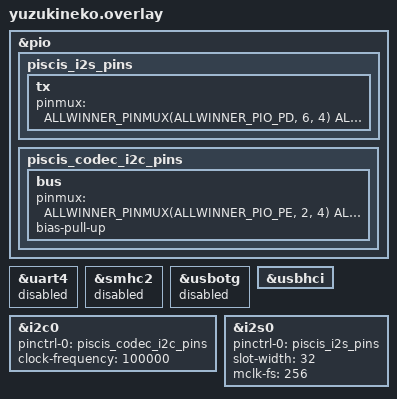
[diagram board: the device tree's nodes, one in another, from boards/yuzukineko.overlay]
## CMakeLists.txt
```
cmake_minimum_required(VERSION 3.20.0)
find_package(Zephyr REQUIRED HINTS $ENV{ZEPHYR_BASE})
project(piscis_standalone)
target_include_directories(app PRIVATE core organ synth)
target_sources(app PRIVATE src/main.cpp src/midi_host.c core/mdaEPiano.cpp)
target_compile_options(app PRIVATE $<$<COMPILE_LANGUAGE:CXX>:-fno-threadsafe-statics>)
```

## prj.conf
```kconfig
CONFIG_CPP=y
CONFIG_STD_CPP17=y
CONFIG_FPU=y
CONFIG_FPU_SHARING=y
CONFIG_CHERRYUSB=y
CONFIG_CHERRYUSB_HOST=y
CONFIG_CHERRYUSB_HOST_EHCI_CUSTOM=y
CONFIG_USBHOST_REQUEST_BUFFER_LEN=2048
CONFIG_I2C=y
CONFIG_I2S=y
CONFIG_DMA=y
CONFIG_MAIN_STACK_SIZE=16384
CONFIG_SYSTEM_WORKQUEUE_STACK_SIZE=2048
CONFIG_HEAP_MEM_POOL_SIZE=131072
CONFIG_CONSOLE=y
CONFIG_UART_CONSOLE=y
CONFIG_PRINTK=y
CONFIG_SHELL=n
CONFIG_DEVMEM_SHELL=n
CONFIG_DISPLAY=n
CONFIG_G2D=n
```

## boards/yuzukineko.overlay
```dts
/* PISCIS carrier layout from eed377f8b195, subject to physical-board check. */
&pio {
    piscis_i2s_pins: piscis_i2s_pins {
        tx {
            pinmux = <ALLWINNER_PINMUX(ALLWINNER_PIO_PD, 6, 4)
                      ALLWINNER_PINMUX(ALLWINNER_PIO_PD, 7, 4)
                      ALLWINNER_PINMUX(ALLWINNER_PIO_PD, 8, 4)
                      ALLWINNER_PINMUX(ALLWINNER_PIO_PD, 9, 4)>;
        };
    };
    piscis_codec_i2c_pins: piscis_codec_i2c_pins {
        bus {
            pinmux = <ALLWINNER_PINMUX(ALLWINNER_PIO_PE, 2, 4)
                      ALLWINNER_PINMUX(ALLWINNER_PIO_PE, 3, 4)>;
            bias-pull-up;
        };
    };
};

&uart4 { status = "disabled"; };
&smhc2 { status = "disabled"; };
&usbotg { status = "disabled"; };
&usbhci { status = "okay"; };

&i2c0 {
    status = "okay";
    pinctrl-0 = <&piscis_codec_i2c_pins>;
    pinctrl-names = "default";
    clock-frequency = <100000>;
};

&i2s0 {
    status = "okay";
    pinctrl-0 = <&piscis_i2s_pins>;
    pinctrl-names = "default";
    slot-width = <32>;
    mclk-fs = <256>;
};
```

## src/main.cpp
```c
#include <zephyr/device.h>
#include <zephyr/drivers/i2c.h>
#include <zephyr/drivers/i2s.h>
#include <zephyr/kernel.h>
#include <zephyr/sys/printk.h>

#include <errno.h>
#include <string.h>
#include "DualSynth.h"
#include "MidiInput.h"

extern "C" {
#include "midi_host.h"
}

namespace {
constexpr unsigned frames = 256;
// Leave two queued blocks after the driver fills its four DMA periods.
constexpr unsigned startup_blocks = 6;
constexpr size_t block_bytes = frames * 2 * sizeof(int16_t);
constexpr uint8_t codec_address = 0x10; // 7-bit I2C address with CE grounded
constexpr uint8_t dac_control3 = 0x19;
constexpr uint8_t dac_mute = 0x04;

const struct device *const i2c = DEVICE_DT_GET(DT_NODELABEL(i2c0));
const struct device *const i2s = DEVICE_DT_GET(DT_NODELABEL(i2s0));
float left[frames], right[frames];
K_MEM_SLAB_DEFINE(audio_blocks, block_bytes, startup_blocks, 64);
K_MSGQ_DEFINE(midi_events, sizeof(struct midi_event), 128, 4);
K_THREAD_STACK_DEFINE(midi_stack, 4096);
struct k_thread midi_thread;

class PlaybackVolume {
    static constexpr float startup_gain = 16.0f;
    static constexpr float max_gain = 80.0f; // +20 dB over the previous 8x maximum
    // Keep some digital peak headroom while letting chords build higher peaks.
    static constexpr float ceiling = 0.82f;
    float gain = startup_gain;
    float target = startup_gain;
    float limiter_gain = 1.0f;
    float pending_peak = 0.0f;
    float pending_left[frames]{};
    float pending_right[frames]{};

    static float magnitude(float sample)
    {
        return sample < 0 ? -sample : sample;
    }

public:
    void set(uint8_t value)
    {
        // Keep finer control at lower levels with the wider gain range.
        const float position = value / 127.0f;
        const float squared_position = position * position;
        target = max_gain * squared_position * squared_position;
    }

    void interleave(int16_t *pcm)
    {
        float peak = 0.0f;
        const float step = (target - gain) / frames;
        for (unsigned i = 0; i < frames; ++i) {
            const float level = gain + step * (i + 1);
            left[i] *= level;
            right[i] *= level;
            const float l = magnitude(left[i]);
            const float r = magnitude(right[i]);
            if (l > peak) peak = l;
            if (r > peak) peak = r;
        }
        gain = target;

        // Delay one block. This lets the gain ramp down before a loud chord
        // arrives, while a slower release keeps it from following the waveform.
        const float largest = peak > pending_peak ? peak : pending_peak;
        const float safe_gain = largest > ceiling ? ceiling / largest : 1.0f;
        const float recovery = limiter_gain + (1.0f - limiter_gain) * 0.08f;
        const float next_gain = recovery < safe_gain ? recovery : safe_gain;
        const float limiter_step = (next_gain - limiter_gain) / frames;
        for (unsigned i = 0; i < frames; ++i) {
            const float level = (limiter_gain + limiter_step * (i + 1)) * 32767.0f;
            pcm[2 * i] = static_cast<int16_t>(pending_left[i] * level);
            pcm[2 * i + 1] = static_cast<int16_t>(pending_right[i] * level);
            pending_left[i] = left[i];
            pending_right[i] = right[i];
        }
        limiter_gain = next_gain;
        pending_peak = peak;
    }
};

PlaybackVolume playback_volume;

int codec_write(uint8_t reg, uint8_t value)
{
    return i2c_reg_write_byte(i2c, codec_address, reg, value);
}

int codec_prepare()
{
    uint8_t reg_value = 0;
    int ret = i2c_reg_read_byte(i2c, codec_address, 0x00, &reg_value);
    if (ret) {
        printk("ES8388 did not respond at 0x10: %d\n", ret);
        return ret;
    }

    // Playback path from the ES8388 register map. CE is strapped low on the
    // PISCIS carrier and J5 is fed by LOUT1/ROUT1.
    constexpr struct { uint8_t reg, value; } setup[] = {
        {dac_control3, dac_mute},
        {0x01, 0x50}, // Reference and analog power
        {0x02, 0x00}, // Chip normal operation
        {0x03, 0xff}, // ADC off
        {0x04, 0xc0}, // DAC and analog outputs off during configuration
        {0x00, 0x12}, // Playback reference configuration
        {0x08, 0x00}, // F101 supplies clocks
        {0x17, 0x18}, // Philips I2S, 16-bit samples
        {0x18, 0x02}, // MCLK = 256 x sample rate
        {0x1a, 0x00}, {0x1b, 0x00}, // Digital playback volume (0 dB)
        {0x26, 0x00},
        {0x27, 0x90}, {0x2a, 0x90}, // Left/right DAC to matching analog mixer
        {0x2b, 0x80}, // Shared LRCK
        {0x2d, 0x00},
        {0x2e, 0x21}, {0x2f, 0x21}, // LOUT1/ROUT1 analog gain +3 dB
        {0x04, 0x30}, // Enable DAC and the LOUT1/ROUT1 pair
    };
    for (const auto &entry : setup) {
        ret = codec_write(entry.reg, entry.value);
        if (ret) {
            printk("ES8388 register 0x%02x failed: %d\n", entry.reg, ret);
            return ret;
        }
    }
    k_msleep(100);
    return 0;
}

int queue_audio(DualSynth *synth)
{
    void *block;
    int ret = k_mem_slab_alloc(&audio_blocks, &block, K_MSEC(100));
    if (ret) return ret;
    if (synth) {
        synth->render(left, right, frames);
        playback_volume.interleave(static_cast<int16_t *>(block));
    } else {
        memset(block, 0, block_bytes);
    }
    ret = i2s_write(i2s, block, block_bytes);
    if (ret) k_mem_slab_free(&audio_blocks, block);
    return ret;
}

int audio_start()
{
    if (!device_is_ready(i2c) || !device_is_ready(i2s)) return -ENODEV;
    int ret = codec_prepare();
    if (ret) return ret;
    const struct i2s_config cfg = {
        .word_size = 16,
        .channels = 2,
        .format = I2S_FMT_DATA_FORMAT_I2S,
        .options = I2S_OPT_BIT_CLK_MASTER | I2S_OPT_FRAME_CLK_MASTER,
        .frame_clk_freq = 44100,
        .mem_slab = &audio_blocks,
        .block_size = block_bytes,
        .timeout = 100,
    };
    ret = i2s_configure(i2s, I2S_DIR_TX, &cfg);
    if (ret) return ret;
    for (unsigned i = 0; i < startup_blocks && !ret; ++i) ret = queue_audio(nullptr);
    if (!ret) ret = i2s_trigger(i2s, I2S_DIR_TX, I2S_TRIGGER_START);
    if (!ret) ret = codec_write(dac_control3, 0x00);
    if (ret) i2s_trigger(i2s, I2S_DIR_TX, I2S_TRIGGER_DROP);
    return ret;
}

void midi_receiver(void *, void *, void *)
{
    const int ret = midi_host_start();
    if (ret) {
        printk("USB host initialization failed: %d\n", ret);
        return;
    }
    for (;;) {
        midi_host_poll();
        k_msleep(1);
    }
}

int play_status_note(DualSynth &synth, int note)
{
    // Render a brief note before accepting live keys. Use the same audio path
    // and gain as normal playback so the two audible checkpoints are meaningful.
    synth.reset();
    synth.noteOn(note, 80);
    for (unsigned i = 0; i < 34; ++i) {
        if (i == 19) synth.noteOn(note, 0);
        const int ret = queue_audio(&synth);
        if (ret) return ret;
    }
    synth.reset();
    return 0;
}

}

extern "C" void midi_event_push(const struct midi_event *event)
{
    if (k_msgq_put(&midi_events, event, K_NO_WAIT) != 0) {
        k_msgq_purge(&midi_events);
        midi_event reset{};
        reset.type = MIDI_RESET;
        k_msgq_put(&midi_events, &reset, K_NO_WAIT);
        k_msgq_put(&midi_events, event, K_NO_WAIT);
    }
}

int main()
{
    static DualSynth synth;
    static MidiInput midi(synth);
    int ret = audio_start();
    if (ret) {
        printk("Headphone output initialization failed: %d\n", ret);
        return ret;
    }
    ret = play_status_note(synth, 60);
    if (ret) {
        codec_write(dac_control3, dac_mute);
        i2s_trigger(i2s, I2S_DIR_TX, I2S_TRIGGER_DROP);
        printk("Startup tone failed: %d\n", ret);
        return ret;
    }
    k_thread_create(&midi_thread, midi_stack, K_THREAD_STACK_SIZEOF(midi_stack),
                    midi_receiver, nullptr, nullptr, nullptr, 5, 0, K_NO_WAIT);
    printk("PISCIS ready: all MIDI channels, ES8388 44100 Hz\n");
    for (;;) {
        midi_event event;
        for (unsigned i = 0; i < 32 && k_msgq_get(&midi_events, &event, K_NO_WAIT) == 0; ++i) {
            if (event.type == MIDI_CONNECTED) {
                midi.reset();
                printk("MIDI keyboard ready, IN=0x%02x\n", event.key);
                ret = play_status_note(synth, 72);
                if (ret) break;
            } else if (event.type == MIDI_DISCONNECTED || event.type == MIDI_RESET) {
                midi.reset();
            } else if (event.type == MIDI_ERROR) {
                printk("MIDI input error: %d\n", event.detail);
            } else if (event.type == MIDI_VOLUME) {
                playback_volume.set(event.value);
            } else {
                midi.apply(event);
            }
        }
        if (!ret) ret = queue_audio(&synth);
        if (ret) {
            codec_write(dac_control3, dac_mute);
            i2s_trigger(i2s, I2S_DIR_TX, I2S_TRIGGER_DROP);
            printk("Audio output stopped: %d\n", ret);
            return ret;
        }
    }
}
```

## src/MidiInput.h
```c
#pragma once

#include <stdint.h>
#include <string.h>
#include "DualSynth.h"

extern "C" {
#include "midi_host.h"
}

// Merge the keyboard's cables and channels into one instrument. Keep note
// ownership per source so releasing a key on one channel cannot silence
// the same pitch while another channel still holds it.
class MidiInput {
    static constexpr unsigned channel_count = 16;
    static constexpr unsigned cable_count = 16;
    static constexpr unsigned note_count = 128;

    struct Source {
        bool held[note_count];
        bool sustain;
    };

    DualSynth &synth;
    Source sources[cable_count][channel_count]{};
    uint16_t note_holders[note_count]{};
    unsigned sustain_sources = 0;

    void clear()
    {
        memset(sources, 0, sizeof(sources));
        memset(note_holders, 0, sizeof(note_holders));
        sustain_sources = 0;
    }

    void release(Source &source, unsigned note)
    {
        if (!source.held[note]) return;
        source.held[note] = false;
        if (--note_holders[note] == 0) synth.noteOn(note, 0);
    }

    void set_sustain(Source &source, bool pressed)
    {
        if (source.sustain == pressed) return;
        const bool was_sustained = sustain_sources != 0;
        source.sustain = pressed;
        if (pressed) {
            ++sustain_sources;
        } else {
            --sustain_sources;
        }
        if (was_sustained != (sustain_sources != 0)) synth.sustain(sustain_sources != 0);
    }

public:
    explicit MidiInput(DualSynth &engine) : synth(engine) {}

    void reset()
    {
        synth.reset();
        clear();
    }

    void apply(const midi_event &event)
    {
        if (event.cable >= cable_count || event.channel >= channel_count ||
            event.key >= note_count) return;
        Source &source = sources[event.cable][event.channel];
        switch (event.type) {
        case MIDI_NOTE_ON:
            if (!source.held[event.key]) {
                source.held[event.key] = true;
                ++note_holders[event.key];
            }
            synth.noteOn(event.key, event.value);
            break;
        case MIDI_NOTE_OFF:
            release(source, event.key);
            break;
        case MIDI_SUSTAIN:
            set_sustain(source, event.value >= 64);
            break;
        case MIDI_PROGRAM:
            if (event.value <= 2 && synth.configure(event.value, 0, 100, 100)) clear();
            break;
        case MIDI_ALL_NOTES_OFF:
            if (event.key == 120) {
                reset();
            } else {
                for (unsigned note = 0; note < note_count; ++note) release(source, note);
            }
            break;
        case MIDI_RESET_CONTROLLERS:
            set_sustain(source, false);
            break;
        default:
            break;
        }
    }
};
```

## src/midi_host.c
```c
#include <zephyr/kernel.h>
/* Both libraries define this helper; retain Zephyr's version outside the header. */
#pragma push_macro("DIV_ROUND_CLOSEST")
#undef DIV_ROUND_CLOSEST
#include "usbh_core.h"
#pragma pop_macro("DIV_ROUND_CLOSEST")
#include "midi_host.h"

/* Initial scope: one MIDI 1.0 streaming interface, alt 0, first Bulk IN.
 * Static storage and a bounded synchronous URB keep teardown simple: the hub
 * disconnect callback waits for at most one read before clearing its pointer.
 */
K_MUTEX_DEFINE(midi_lock);
static struct usbh_hubport *port;
static struct usb_endpoint_descriptor *input_ep;
static struct usbh_urb read_urb;
static bool stopped;
static uint8_t rx[512] USB_MEM_ALIGNX;
extern uintptr_t usb_sunxi_ehci_base(void);

static void emit(uint8_t type, uint8_t cable, uint8_t channel,
                 uint8_t key, uint8_t value, int detail)
{
    const struct midi_event event = {
        .time_ms = k_uptime_get_32(), .type = type, .cable = cable,
        .channel = channel, .key = key, .value = value, .detail = detail
    };
    midi_event_push(&event);
}

/* Validate the class-specific MS header, not just the generic Audio class. */
static bool is_midi1(struct usbh_hubport *p, uint8_t number)
{
    const uint8_t *d = p->raw_config_desc;
    const size_t total = p->config.config_desc.wTotalLength;
    bool selected = false, found = false;
    if (!d || total < 9 || total >= CONFIG_USBHOST_REQUEST_BUFFER_LEN)
        return false;
    for (size_t i = 0; i < total;) {
        if (total - i < 2 || d[i] < 2 || d[i] > total - i)
            return false;
        const uint8_t len = d[i], type = d[i + 1];
        if (type == 4) {
            if (len < 9) return false;
            selected = d[i + 2] == number && d[i + 3] == 0 &&
                       d[i + 5] == 1 && d[i + 6] == 3 && d[i + 7] == 0;
        } else if (selected && type == 0x24 && len >= 3 && d[i + 2] == 1) {
            if (len < 7 || d[i + 3] != 0 || d[i + 4] != 1)
                return false;
            found = true;
        }
        i += len;
    }
    return found;
}

static int midi_connect(struct usbh_hubport *p, uint8_t intf)
{
    if (intf >= CONFIG_USBHOST_MAX_INTERFACES) return -USB_ERR_INVAL;
    struct usbh_interface *iface = &p->config.intf[intf];
    struct usbh_interface_altsetting *alt = &iface->altsetting[0];
    struct usb_endpoint_descriptor *ep = NULL;
    if (!iface->altsetting_num || alt->intf_desc.bAlternateSetting != 0 ||
        !is_midi1(p, alt->intf_desc.bInterfaceNumber)) {
        printk("MIDI: unsupported descriptor (requires MIDI 1.0 alt 0)\n");
        return -USB_ERR_NOTSUPP;
    }
    unsigned count = alt->intf_desc.bNumEndpoints;
    if (count > CONFIG_USBHOST_MAX_ENDPOINTS) return -USB_ERR_INVAL;
    for (unsigned i = 0; i < count; ++i) {
        struct usb_endpoint_descriptor *candidate = &alt->ep[i].ep_desc;
        if ((candidate->bEndpointAddress & 0x80) &&
            (candidate->bmAttributes & 3) == 2) {
            ep = candidate;
            break;
        }
    }
    if (!ep || ep->wMaxPacketSize < 4 || ep->wMaxPacketSize > sizeof(rx) ||
        ep->wMaxPacketSize % 4) return -USB_ERR_NOTSUPP;

    k_mutex_lock(&midi_lock, K_FOREVER);
    if (port) {
        k_mutex_unlock(&midi_lock);
        printk("MIDI: only one streaming interface is supported\n");
        return -USB_ERR_BUSY;
    }
    memset(&read_urb, 0, sizeof(read_urb));
    port = p;
    input_ep = ep;
    stopped = false;
    iface->priv = &read_urb;
    emit(MIDI_CONNECTED, 0, 0, ep->bEndpointAddress, p->dev_addr,
         ep->wMaxPacketSize);
    k_mutex_unlock(&midi_lock);
    return 0;
}

static int midi_disconnect(struct usbh_hubport *p, uint8_t intf)
{
    k_mutex_lock(&midi_lock, K_FOREVER);
    if (intf < CONFIG_USBHOST_MAX_INTERFACES &&
        port == p && p->config.intf[intf].priv == &read_urb) {
        /* No URB is pending: poll holds this lock through synchronous completion. */
        p->config.intf[intf].priv = NULL;
        port = NULL;
        input_ep = NULL;
        stopped = false;
        emit(MIDI_DISCONNECTED, 0, 0, 0, 0, 0);
    }
    k_mutex_unlock(&midi_lock);
    return 0;
}

static const struct usbh_class_driver midi_driver = {
    .driver_name = "midi1", .connect = midi_connect, .disconnect = midi_disconnect
};

CLASS_INFO_DEFINE const struct usbh_class_info f101_midi1_info = {
    .match_flags = USB_CLASS_MATCH_INTF_CLASS | USB_CLASS_MATCH_INTF_SUBCLASS |
                   USB_CLASS_MATCH_INTF_PROTOCOL,
    .bInterfaceClass = 0x01, .bInterfaceSubClass = 0x03,
    .bInterfaceProtocol = 0x00, .id_table = NULL, .class_driver = &midi_driver
};

static bool is_volume_controller(uint8_t controller)
{
    if (controller == 7) return true;
    // This Keystation Mini 32 uses a stored custom assignment for its knob.
    // Keep CC79 device-specific because other controllers may use it for sound.
    return controller == 79 && port->device_desc.idVendor == 0x0a4d &&
           port->device_desc.idProduct == 0x129d;
}

static bool decode(const uint8_t *b)
{
    const uint8_t cin = b[0] & 15, cable = b[0] >> 4;
    const uint8_t command = b[1] >> 4, channel = b[1] & 15;
    /* Ignore message types outside the standalone instrument's controls. */
    if (cin != 8 && cin != 9 && cin != 11 && cin != 12) return true;
    if (command != cin || (b[2] & 0x80) || (cin != 12 && (b[3] & 0x80))) return false;
    if (cin == 12) {
        emit(MIDI_PROGRAM, cable, channel, 0, b[2], 0);
        return true;
    }
    if (cin == 8 || (cin == 9 && b[3] == 0))
        emit(MIDI_NOTE_OFF, cable, channel, b[2], b[3], 0);
    else if (cin == 9)
        emit(MIDI_NOTE_ON, cable, channel, b[2], b[3], 0);
    else if (is_volume_controller(b[2]))
        emit(MIDI_VOLUME, cable, channel, b[2], b[3], 0);
    else if (b[2] == 64)
        emit(MIDI_SUSTAIN, cable, channel, 64, b[3], 0);
    else if (b[2] == 120 || b[2] == 123)
        emit(MIDI_ALL_NOTES_OFF, cable, channel, b[2], b[3], 0);
    else if (b[2] == 121)
        emit(MIDI_RESET_CONTROLLERS, cable, channel, b[2], b[3], 0);
    return true;
}

void midi_host_poll(void)
{
    k_mutex_lock(&midi_lock, K_FOREVER);
    if (port && port->connected && !stopped) {
        read_urb.actual_length = 0;
        usbh_bulk_urb_fill(&read_urb, port, input_ep, rx,
                           input_ep->wMaxPacketSize, 50, NULL, NULL);
        const int ret = usbh_submit_urb(&read_urb);
        if (ret == 0) {
            const uint32_t length = read_urb.actual_length;
            if (length > sizeof(rx) || length % 4) {
                emit(MIDI_ERROR, 0, 0, 0, 0, -USB_ERR_INVAL);
            } else {
                unsigned bad = 0;
                for (uint32_t i = 0; i < length; i += 4)
                    if (!decode(rx + i)) ++bad;
                if (bad) emit(MIDI_ERROR, 0, 0, 0, 0, -USB_ERR_INVAL);
            }
        } else if (ret != -USB_ERR_TIMEOUT && ret != -USB_ERR_NAK) {
            /* Stop on STALL/transport error instead of busy-looping or retaining
             * notes. First-stage recovery is unplug/replug, explicitly logged. */
            stopped = true;
            emit(MIDI_ERROR, 0, 0, 0, 0, ret);
            emit(MIDI_RESET, 0, 0, 0, 0, ret);
        }
    }
    k_mutex_unlock(&midi_lock);
}

int midi_host_start(void)
{
    return usbh_initialize(0, usb_sunxi_ehci_base(), NULL);
}
```

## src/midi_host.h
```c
#ifndef MIDI_HOST_H
#define MIDI_HOST_H
#include <stdint.h>

enum midi_event_type {
    MIDI_CONNECTED, MIDI_DISCONNECTED, MIDI_NOTE_ON, MIDI_NOTE_OFF,
    MIDI_SUSTAIN, MIDI_RESET, MIDI_ERROR, MIDI_PROGRAM, MIDI_ALL_NOTES_OFF,
    MIDI_RESET_CONTROLLERS, MIDI_VOLUME
};

struct midi_event {
    uint32_t time_ms;
    int32_t detail;
    uint8_t type, cable, channel, key, value;
};

int midi_host_start(void);
void midi_host_poll(void);
/* Called only from thread context; implementation must never block. */
void midi_event_push(const struct midi_event *event);
#endif
```
